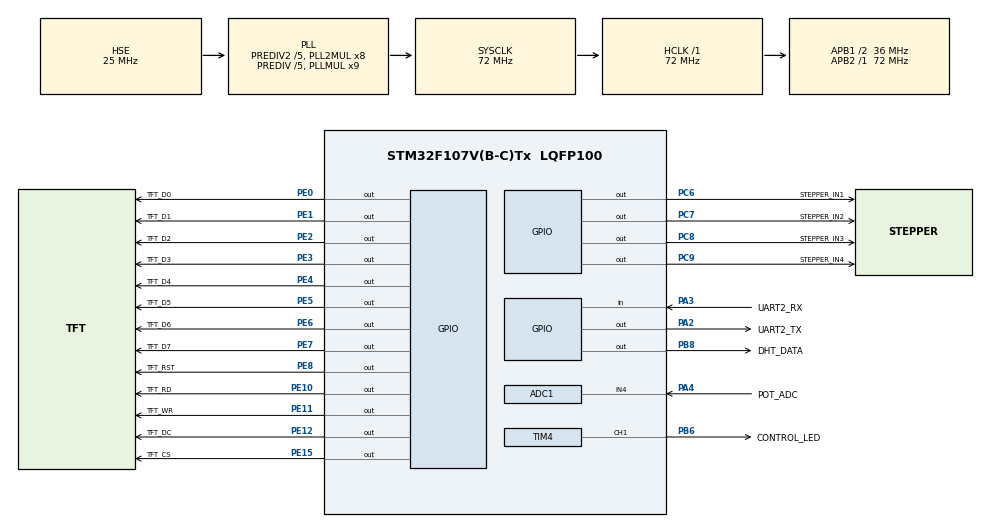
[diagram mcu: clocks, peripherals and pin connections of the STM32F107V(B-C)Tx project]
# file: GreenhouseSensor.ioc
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ADC1.Channel-0\#ChannelRegularConversion=ADC_CHANNEL_4
ADC1.ContinuousConvMode=DISABLE
ADC1.DiscontinuousConvMode=DISABLE
ADC1.EnableRegularConversion=ENABLE
ADC1.ExternalTrigConv=ADC_SOFTWARE_START
ADC1.NbrOfConversion=1
ADC1.NbrOfConversionFlag=1
ADC1.Rank-0\#ChannelRegularConversion=1
ADC1.SamplingTime-0\#ChannelRegularConversion=ADC_SAMPLETIME_239CYCLES_5
ADC1.master=1
Mcu.Family=STM32F1
Mcu.Name=STM32F107V(B-C)Tx
Mcu.Package=LQFP100
NVIC.PriorityGroup=NVIC_PRIORITYGROUP_4
OSC_IN.Mode=HSE-External-Oscillator
OSC_IN.Signal=RCC_OSC_IN
OSC_OUT.Mode=HSE-External-Oscillator
OSC_OUT.Signal=RCC_OSC_OUT
PA4.GPIO_Label=POT_ADC
PA4.Signal=ADCx_IN4
PA13.Mode=Serial_Wire
PA13.Signal=SYS_JTMS-SWDIO
PA14.Mode=Serial_Wire
PA14.Signal=SYS_JTCK-SWCLK
PB6.GPIO_Label=CONTROL_LED
PB6.Signal=S_TIM4_CH1
PB8.GPIO_Label=DHT_DATA
PB8.GPIO_ModeDefaultOutputPP=GPIO_MODE_OUTPUT_OD
PB8.PinState=GPIO_PIN_SET
PB8.Signal=GPIO_Output
PC6.GPIO_Label=STEPPER_IN1
PC6.PinState=GPIO_PIN_RESET
PC6.Signal=GPIO_Output
PC7.GPIO_Label=STEPPER_IN2
PC7.PinState=GPIO_PIN_RESET
PC7.Signal=GPIO_Output
PC8.GPIO_Label=STEPPER_IN3
PC8.PinState=GPIO_PIN_RESET
PC8.Signal=GPIO_Output
PC9.GPIO_Label=STEPPER_IN4
PC9.PinState=GPIO_PIN_RESET
PC9.Signal=GPIO_Output
PE0.GPIO_Label=TFT_D0
PE0.GPIO_Speed=GPIO_SPEED_FREQ_HIGH
PE0.PinState=GPIO_PIN_RESET
PE0.Signal=GPIO_Output
PE1.GPIO_Label=TFT_D1
PE1.GPIO_Speed=GPIO_SPEED_FREQ_HIGH
PE1.PinState=GPIO_PIN_RESET
PE1.Signal=GPIO_Output
PE10.GPIO_Label=TFT_RD
PE10.GPIO_Speed=GPIO_SPEED_FREQ_HIGH
PE10.PinState=GPIO_PIN_SET
PE10.Signal=GPIO_Output
PE11.GPIO_Label=TFT_WR
PE11.GPIO_Speed=GPIO_SPEED_FREQ_HIGH
PE11.PinState=GPIO_PIN_SET
PE11.Signal=GPIO_Output
PE12.GPIO_Label=TFT_DC
PE12.GPIO_Speed=GPIO_SPEED_FREQ_HIGH
PE12.PinState=GPIO_PIN_SET
PE12.Signal=GPIO_Output
PE15.GPIO_Label=TFT_CS
PE15.GPIO_Speed=GPIO_SPEED_FREQ_HIGH
PE15.PinState=GPIO_PIN_SET
PE15.Signal=GPIO_Output
PE2.GPIO_Label=TFT_D2
PE2.GPIO_Speed=GPIO_SPEED_FREQ_HIGH
PE2.PinState=GPIO_PIN_RESET
PE2.Signal=GPIO_Output
PE3.GPIO_Label=TFT_D3
PE3.GPIO_Speed=GPIO_SPEED_FREQ_HIGH
PE3.PinState=GPIO_PIN_RESET
PE3.Signal=GPIO_Output
PE4.GPIO_Label=TFT_D4
PE4.GPIO_Speed=GPIO_SPEED_FREQ_HIGH
PE4.PinState=GPIO_PIN_RESET
PE4.Signal=GPIO_Output
PE5.GPIO_Label=TFT_D5
PE5.GPIO_Speed=GPIO_SPEED_FREQ_HIGH
PE5.PinState=GPIO_PIN_RESET
PE5.Signal=GPIO_Output
PE6.GPIO_Label=TFT_D6
PE6.GPIO_Speed=GPIO_SPEED_FREQ_HIGH
PE6.PinState=GPIO_PIN_RESET
PE6.Signal=GPIO_Output
PE7.GPIO_Label=TFT_D7
PE7.GPIO_Speed=GPIO_SPEED_FREQ_HIGH
PE7.PinState=GPIO_PIN_RESET
PE7.Signal=GPIO_Output
PE8.GPIO_Label=TFT_RST
PE8.GPIO_Speed=GPIO_SPEED_FREQ_HIGH
PE8.PinState=GPIO_PIN_SET
PE8.Signal=GPIO_Output
ProjectManager.HeapSize=0x200
ProjectManager.StackSize=0x800
ProjectManager.TargetToolchain=Makefile
RCC.ADCPresc=RCC_ADCPCLK2_DIV6
RCC.AHBCLKDivider=RCC_SYSCLK_DIV1
RCC.AHBFreq_Value=72000000
RCC.APB1CLKDivider=RCC_HCLK_DIV2
RCC.APB1Freq_Value=36000000
RCC.APB1TimFreq_Value=72000000
RCC.APB2CLKDivider=RCC_HCLK_DIV1
RCC.APB2Freq_Value=72000000
RCC.APB2TimFreq_Value=72000000
RCC.HCLKFreq_Value=72000000
RCC.HSEDivPLL=RCC_HSE_PREDIV_DIV5
RCC.HSE_VALUE=25000000
RCC.PLL2Mul=RCC_PLL2_MUL8
RCC.PLLMUL=RCC_PLL_MUL9
RCC.PLLSourceVirtual=RCC_PLLSOURCE_HSE
RCC.Prediv1Source=RCC_PREDIV1_SOURCE_PLL2
RCC.Prediv2=RCC_HSE_PREDIV2_DIV5
RCC.SYSCLKFreq_VALUE=72000000
RCC.SYSCLKSource=RCC_SYSCLKSOURCE_PLLCLK
RCC.USBFreq_Value=48000000
SH.ADCx_IN4.0=ADC1_IN4,IN4
SH.S_TIM3_CH1.0=TIM3_CH1,PWM Generation1 CH1
SH.S_TIM4_CH1.0=TIM4_CH1,PWM Generation1 CH1
TIM2.Period=65535
TIM2.Prescaler=71
TIM4.Channel-PWM Generation1 CH1=TIM_CHANNEL_1
TIM4.Period=999
TIM4.Prescaler=71
TIM4.Pulse-PWM Generation1 CH1=0
VP_TIM2_VS_ClockSourceINT.Mode=Internal
board=custom
PA2.GPIO_Label=UART2_TX
PA2.Signal=GPIO_Output
PA3.GPIO_Label=UART2_RX
PA3.Signal=GPIO_Input

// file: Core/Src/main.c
/* USER CODE BEGIN Header */
/**
  ******************************************************************************
  * @file           : main.c
  * @brief          : Main program body
  ******************************************************************************
  * @attention
  *
  * Copyright (c) 2026 STMicroelectronics.
  * All rights reserved.
  *
  * This software is licensed under terms that can be found in the LICENSE file
  * in the root directory of this software component.
  * If no LICENSE file comes with this software, it is provided AS-IS.
  *
  ******************************************************************************
  */
/* USER CODE END Header */
#include "main.h"

/* USER CODE BEGIN Includes */
#include "monitor.h"

/* USER CODE END Includes */

ADC_HandleTypeDef hadc1;

TIM_HandleTypeDef htim2;
TIM_HandleTypeDef htim3;
TIM_HandleTypeDef htim4;

void SystemClock_Config(void);
static void MX_GPIO_Init(void);
static void MX_ADC1_Init(void);
static void MX_TIM2_Init(void);

static void MX_TIM4_Init(void);
void HAL_TIM_MspPostInit(TIM_HandleTypeDef *htim);

int main(void)
{

  /* MCU Configuration--------------------------------------------------------*/

  /* Reset of all peripherals, Initializes the Flash interface and the Systick. */
  HAL_Init();

  /* Configure the system clock */
  SystemClock_Config();

  /* Initialize all configured peripherals */
  MX_GPIO_Init();
  MX_ADC1_Init();
  MX_TIM2_Init();

  MX_TIM4_Init();
  /* USER CODE BEGIN 2 */
  Monitor_Init();

  /* USER CODE END 2 */

  /* Infinite loop */
  while (1)
  {

    /* USER CODE BEGIN 3 */
    Monitor_Run();
  }
  /* USER CODE END 3 */
}

void SystemClock_Config(void)
{
  RCC_OscInitTypeDef RCC_OscInitStruct = {0};
  RCC_ClkInitTypeDef RCC_ClkInitStruct = {0};
  RCC_PeriphCLKInitTypeDef PeriphClkInit = {0};

  /** Initializes the RCC Oscillators according to the specified parameters
  * in the RCC_OscInitTypeDef structure.
  */
  RCC_OscInitStruct.OscillatorType = RCC_OSCILLATORTYPE_HSE;
  RCC_OscInitStruct.HSEState = RCC_HSE_ON;
  RCC_OscInitStruct.HSEPredivValue = RCC_HSE_PREDIV_DIV5;
  RCC_OscInitStruct.HSIState = RCC_HSI_ON;
  RCC_OscInitStruct.Prediv1Source = RCC_PREDIV1_SOURCE_PLL2;
  RCC_OscInitStruct.PLL.PLLState = RCC_PLL_ON;
  RCC_OscInitStruct.PLL.PLLSource = RCC_PLLSOURCE_HSE;
  RCC_OscInitStruct.PLL.PLLMUL = RCC_PLL_MUL9;
  RCC_OscInitStruct.PLL2.PLL2State = RCC_PLL2_ON;
  RCC_OscInitStruct.PLL2.PLL2MUL = RCC_PLL2_MUL8;
  RCC_OscInitStruct.PLL2.HSEPrediv2Value = RCC_HSE_PREDIV2_DIV5;
  if (HAL_RCC_OscConfig(&RCC_OscInitStruct) != HAL_OK)
  {
    Error_Handler();
  }

  /** Initializes the CPU, AHB and APB buses clocks
  */
  RCC_ClkInitStruct.ClockType = RCC_CLOCKTYPE_HCLK|RCC_CLOCKTYPE_SYSCLK
                              |RCC_CLOCKTYPE_PCLK1|RCC_CLOCKTYPE_PCLK2;
  RCC_ClkInitStruct.SYSCLKSource = RCC_SYSCLKSOURCE_PLLCLK;
  RCC_ClkInitStruct.AHBCLKDivider = RCC_SYSCLK_DIV1;
  RCC_ClkInitStruct.APB1CLKDivider = RCC_HCLK_DIV2;
  RCC_ClkInitStruct.APB2CLKDivider = RCC_HCLK_DIV1;

  if (HAL_RCC_ClockConfig(&RCC_ClkInitStruct, FLASH_LATENCY_2) != HAL_OK)
  {
    Error_Handler();
  }
  PeriphClkInit.PeriphClockSelection = RCC_PERIPHCLK_ADC;
  PeriphClkInit.AdcClockSelection = RCC_ADCPCLK2_DIV6;
  if (HAL_RCCEx_PeriphCLKConfig(&PeriphClkInit) != HAL_OK)
  {
    Error_Handler();
  }

  /** Configure the Systick interrupt time
  */
}

static void MX_ADC1_Init(void)
{

  ADC_ChannelConfTypeDef sConfig = {0};

  /** Common config
  */
  hadc1.Instance = ADC1;
  hadc1.Init.ScanConvMode = ADC_SCAN_DISABLE;
  hadc1.Init.ContinuousConvMode = DISABLE;
  hadc1.Init.DiscontinuousConvMode = DISABLE;
  hadc1.Init.ExternalTrigConv = ADC_SOFTWARE_START;
  hadc1.Init.DataAlign = ADC_DATAALIGN_RIGHT;
  hadc1.Init.NbrOfConversion = 1;
  if (HAL_ADC_Init(&hadc1) != HAL_OK)
  {
    Error_Handler();
  }

  /** Configure Regular Channel
  */
  sConfig.Channel = ADC_CHANNEL_4;
  sConfig.Rank = ADC_REGULAR_RANK_1;
  sConfig.SamplingTime = ADC_SAMPLETIME_239CYCLES_5;
  if (HAL_ADC_ConfigChannel(&hadc1, &sConfig) != HAL_OK)
  {
    Error_Handler();
  }

}

static void MX_TIM2_Init(void)
{

  TIM_ClockConfigTypeDef sClockSourceConfig = {0};
  TIM_MasterConfigTypeDef sMasterConfig = {0};

  htim2.Instance = TIM2;
  htim2.Init.Prescaler = 71;
  htim2.Init.CounterMode = TIM_COUNTERMODE_UP;
  htim2.Init.Period = 65535;
  htim2.Init.ClockDivision = TIM_CLOCKDIVISION_DIV1;
  htim2.Init.AutoReloadPreload = TIM_AUTORELOAD_PRELOAD_DISABLE;
  if (HAL_TIM_Base_Init(&htim2) != HAL_OK)
  {
    Error_Handler();
  }
  sClockSourceConfig.ClockSource = TIM_CLOCKSOURCE_INTERNAL;
  if (HAL_TIM_ConfigClockSource(&htim2, &sClockSourceConfig) != HAL_OK)
  {
    Error_Handler();
  }
  sMasterConfig.MasterOutputTrigger = TIM_TRGO_RESET;
  sMasterConfig.MasterSlaveMode = TIM_MASTERSLAVEMODE_DISABLE;
  if (HAL_TIMEx_MasterConfigSynchronization(&htim2, &sMasterConfig) != HAL_OK)
  {
    Error_Handler();
  }

}

/** TIM3 CH1: 50 Hz servo pulses on PA6, initially 1000 us (CLOSED). */

/** TIM4 CH1: 1 kHz PWM on PB6, initially OFF. Mirrors the IOC settings. */
static void MX_TIM4_Init(void)
{
  TIM_MasterConfigTypeDef sMasterConfig = {0};
  TIM_OC_InitTypeDef sConfigOC = {0};

  htim4.Instance = TIM4;
  htim4.Init.Prescaler = 71;
  htim4.Init.CounterMode = TIM_COUNTERMODE_UP;
  htim4.Init.Period = 999;
  htim4.Init.ClockDivision = TIM_CLOCKDIVISION_DIV1;
  htim4.Init.AutoReloadPreload = TIM_AUTORELOAD_PRELOAD_DISABLE;
  if (HAL_TIM_PWM_Init(&htim4) != HAL_OK) Error_Handler();

  sMasterConfig.MasterOutputTrigger = TIM_TRGO_RESET;
  sMasterConfig.MasterSlaveMode = TIM_MASTERSLAVEMODE_DISABLE;
  if (HAL_TIMEx_MasterConfigSynchronization(&htim4, &sMasterConfig) != HAL_OK)
    Error_Handler();
  sConfigOC.OCMode = TIM_OCMODE_PWM1;
  sConfigOC.Pulse = 0;
  sConfigOC.OCPolarity = TIM_OCPOLARITY_HIGH;
  sConfigOC.OCFastMode = TIM_OCFAST_DISABLE;
  if (HAL_TIM_PWM_ConfigChannel(&htim4, &sConfigOC, TIM_CHANNEL_1) != HAL_OK)
    Error_Handler();
  HAL_TIM_MspPostInit(&htim4);
}

static void MX_GPIO_Init(void)
{
  GPIO_InitTypeDef GPIO_InitStruct = {0};

  /* GPIO Ports Clock Enable */
  __HAL_RCC_GPIOE_CLK_ENABLE();
  __HAL_RCC_GPIOA_CLK_ENABLE();
  __HAL_RCC_GPIOB_CLK_ENABLE();
  __HAL_RCC_GPIOC_CLK_ENABLE();

  /*Configure GPIO pin Output Level */
  HAL_GPIO_WritePin(GPIOE, TFT_D2_Pin|TFT_D3_Pin|TFT_D4_Pin|TFT_D5_Pin
                          |TFT_D6_Pin|TFT_D7_Pin|TFT_D0_Pin|TFT_D1_Pin, GPIO_PIN_RESET);

  /*Configure GPIO pin Output Level */
  HAL_GPIO_WritePin(GPIOE, TFT_RST_Pin|TFT_RD_Pin|TFT_WR_Pin|TFT_DC_Pin
                          |TFT_CS_Pin, GPIO_PIN_SET);

  /*Configure GPIO pin Output Level */
  HAL_GPIO_WritePin(DHT_DATA_GPIO_Port, DHT_DATA_Pin, GPIO_PIN_SET);

  /*Configure GPIO pins : TFT_D2_Pin TFT_D3_Pin TFT_D4_Pin TFT_D5_Pin
                           TFT_D6_Pin TFT_D7_Pin TFT_RST_Pin TFT_RD_Pin
                           TFT_WR_Pin TFT_DC_Pin TFT_CS_Pin TFT_D0_Pin
                           TFT_D1_Pin */
  GPIO_InitStruct.Pin = TFT_D2_Pin|TFT_D3_Pin|TFT_D4_Pin|TFT_D5_Pin
                          |TFT_D6_Pin|TFT_D7_Pin|TFT_RST_Pin|TFT_RD_Pin
                          |TFT_WR_Pin|TFT_DC_Pin|TFT_CS_Pin|TFT_D0_Pin
                          |TFT_D1_Pin;
  GPIO_InitStruct.Mode = GPIO_MODE_OUTPUT_PP;
  GPIO_InitStruct.Pull = GPIO_NOPULL;
  GPIO_InitStruct.Speed = GPIO_SPEED_FREQ_HIGH;
  HAL_GPIO_Init(GPIOE, &GPIO_InitStruct);

  /*Configure GPIO pin : DHT_DATA_Pin */
  GPIO_InitStruct.Pin = DHT_DATA_Pin;
  GPIO_InitStruct.Mode = GPIO_MODE_OUTPUT_OD;
  GPIO_InitStruct.Pull = GPIO_NOPULL;
  GPIO_InitStruct.Speed = GPIO_SPEED_FREQ_LOW;
  HAL_GPIO_Init(DHT_DATA_GPIO_Port, &GPIO_InitStruct);

  /* ULN2003 inputs start LOW (all motor coils off). */
  HAL_GPIO_WritePin(STEPPER_GPIO_Port, STEPPER_IN1_Pin | STEPPER_IN2_Pin |
                   STEPPER_IN3_Pin | STEPPER_IN4_Pin, GPIO_PIN_RESET);
  GPIO_InitStruct.Pin = STEPPER_IN1_Pin | STEPPER_IN2_Pin |
                        STEPPER_IN3_Pin | STEPPER_IN4_Pin;
  GPIO_InitStruct.Mode = GPIO_MODE_OUTPUT_PP;
  GPIO_InitStruct.Pull = GPIO_NOPULL;
  GPIO_InitStruct.Speed = GPIO_SPEED_FREQ_LOW;
  HAL_GPIO_Init(STEPPER_GPIO_Port, &GPIO_InitStruct);

}

void Error_Handler(void)
{
  __disable_irq();
  while (1)
  {
  }
}
